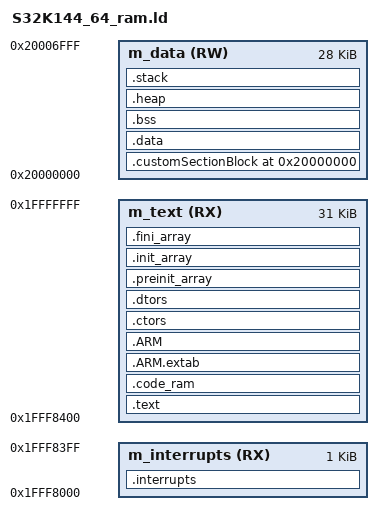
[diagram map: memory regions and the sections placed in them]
/*
** ###################################################################
**     Processor:           S32K144 with 64 KB SRAM
**     Compiler:            GNU C Compiler
**
**     Abstract:
**         Linker file for the GNU C Compiler
**
**     Copyright (c) 2015-2016 Freescale Semiconductor, Inc.
**     Copyright 2017 NXP
**     All rights reserved.
**
**     THIS SOFTWARE IS PROVIDED BY NXP "AS IS" AND ANY EXPRESSED OR
**     IMPLIED WARRANTIES, INCLUDING, BUT NOT LIMITED TO, THE IMPLIED WARRANTIES
**     OF MERCHANTABILITY AND FITNESS FOR A PARTICULAR PURPOSE ARE DISCLAIMED.
**     IN NO EVENT SHALL NXP OR ITS CONTRIBUTORS BE LIABLE FOR ANY DIRECT,
**     INDIRECT, INCIDENTAL, SPECIAL, EXEMPLARY, OR CONSEQUENTIAL DAMAGES
**     (INCLUDING, BUT NOT LIMITED TO, PROCUREMENT OF SUBSTITUTE GOODS OR
**     SERVICES; LOSS OF USE, DATA, OR PROFITS; OR BUSINESS INTERRUPTION)
**     HOWEVER CAUSED AND ON ANY THEORY OF LIABILITY, WHETHER IN CONTRACT,
**     STRICT LIABILITY, OR TORT (INCLUDING NEGLIGENCE OR OTHERWISE) ARISING
**     IN ANY WAY OUT OF THE USE OF THIS SOFTWARE, EVEN IF ADVISED OF
**     THE POSSIBILITY OF SUCH DAMAGE.
**
**     http:                 www.freescale.com
**     mail:                 support@freescale.com
**
** ###################################################################
*/

/* Entry Point */
ENTRY(Reset_Handler)

/*
To use "new" operator with EWL in C++ project the following symbol shall be defined
*/
/*EXTERN(_ZN10__cxxabiv119__terminate_handlerE)*/

HEAP_SIZE  = DEFINED(__heap_size__)  ? __heap_size__  : 0x00000400;
STACK_SIZE = DEFINED(__stack_size__) ? __stack_size__ : 0x00000400;

/* Specify the memory areas */
MEMORY
{
  /* SRAM_L */
  m_interrupts          (RX)  : ORIGIN = 0x1FFF8000, LENGTH = 0x00000400
  m_text                (RX)  : ORIGIN = 0x1FFF8400, LENGTH = 0x00007C00

  /* SRAM_U */
  m_data                (RW)  : ORIGIN = 0x20000000, LENGTH = 0x00007000
}

/* Define output sections */
SECTIONS
{
  /* The startup code goes first into internal RAM */
  .interrupts :
  {
    __VECTOR_TABLE = .;
    __interrupts_start__ = .;
    . = ALIGN(4);
    KEEP(*(.isr_vector))     /* Startup code */
    __interrupts_end__ = .;
    . = ALIGN(4);
  } > m_interrupts

  __VECTOR_RAM = __VECTOR_TABLE;
  __RAM_VECTOR_TABLE_SIZE = 0x0;

  /* The program code and other data goes into internal RAM */
  .text :
  {
    . = ALIGN(4);
    *(.text)                 /* .text sections (code) */
    *(.text*)                /* .text* sections (code) */
    *(.rodata)               /* .rodata sections (constants, strings, etc.) */
    *(.rodata*)              /* .rodata* sections (constants, strings, etc.) */
    *(.glue_7)               /* glue arm to thumb code */
    *(.glue_7t)              /* glue thumb to arm code */
    *(.eh_frame)
    KEEP (*(.init))
    KEEP (*(.fini))
    . = ALIGN(4);
  } > m_text

  /* Section for storing functions that needs to execute from RAM */
  .code_ram :
  {
    . = ALIGN(4);
    __CODE_RAM = .;
    __code_ram_start__ = .;
    *(.code_ram)               /* Custom section for storing code in RAM */
    __CODE_ROM = .;            /* Symbol is used by start-up for data initialization. */
    __CODE_END = .;            /* No copy */
    __code_ram_end__ = .;
    . = ALIGN(4);
  } > m_text

  .ARM.extab :
  {
    *(.ARM.extab* .gnu.linkonce.armextab.*)
  } > m_text

  .ARM :
  {
    __exidx_start = .;
    *(.ARM.exidx*)
    __exidx_end = .;
  } > m_text

 .ctors :
  {
    __CTOR_LIST__ = .;
    /* gcc uses crtbegin.o to find the start of
       the constructors, so we make sure it is
       first.  Because this is a wildcard, it
       doesn't matter if the user does not
       actually link against crtbegin.o; the
       linker won't look for a file to match a
       wildcard.  The wildcard also means that it
       doesn't matter which directory crtbegin.o
       is in.  */
    KEEP (*crtbegin.o(.ctors))
    KEEP (*crtbegin?.o(.ctors))
    /* We don't want to include the .ctor section from
       from the crtend.o file until after the sorted ctors.
       The .ctor section from the crtend file contains the
       end of ctors marker and it must be last */
    KEEP (*(EXCLUDE_FILE(*crtend?.o *crtend.o) .ctors))
    KEEP (*(SORT(.ctors.*)))
    KEEP (*(.ctors))
    __CTOR_END__ = .;
  } > m_text

  .dtors :
  {
    __DTOR_LIST__ = .;
    KEEP (*crtbegin.o(.dtors))
    KEEP (*crtbegin?.o(.dtors))
    KEEP (*(EXCLUDE_FILE(*crtend?.o *crtend.o) .dtors))
    KEEP (*(SORT(.dtors.*)))
    KEEP (*(.dtors))
    __DTOR_END__ = .;
  } > m_text

  .preinit_array :
  {
    PROVIDE_HIDDEN (__preinit_array_start = .);
    KEEP (*(.preinit_array*))
    PROVIDE_HIDDEN (__preinit_array_end = .);
  } > m_text

  .init_array :
  {
    PROVIDE_HIDDEN (__init_array_start = .);
    KEEP (*(SORT(.init_array.*)))
    KEEP (*(.init_array*))
    PROVIDE_HIDDEN (__init_array_end = .);
  } > m_text

  .fini_array :
  {
    PROVIDE_HIDDEN (__fini_array_start = .);
    KEEP (*(SORT(.fini_array.*)))
    KEEP (*(.fini_array*))
    PROVIDE_HIDDEN (__fini_array_end = .);
  } > m_text

  __etext = .;    /* Define a global symbol at end of code. */
  __DATA_ROM = .; /* Symbol is used by startup for data initialization. */
  __DATA_END = __DATA_ROM; /* No copy */

  /* Custom Section Block that can be used to place data at absolute address. */
  /* Use __attribute__((section (".customSection"))) to place data here. */
  .customSectionBlock  ORIGIN(m_data) :
  {
    __customSection_start__ = .;
    KEEP(*(.customSection))  /* Keep section even if not referenced. */
    __customSection_end__ = .;
    __CUSTOM_ROM = .;
    __CUSTOM_END = .;
  } > m_data

  .data :
  {
    . = ALIGN(4);
    __DATA_RAM = .;
    __data_start__ = .;      /* Create a global symbol at data start. */
    *(.data)                 /* .data sections */
    *(.data*)                /* .data* sections */
    KEEP(*(.jcr*))
    . = ALIGN(4);
    __data_end__ = .;        /* Define a global symbol at data end. */
  } > m_data

  /* Uninitialized data section. */
  .bss :
  {
    /* This is used by the startup in order to initialize the .bss section. */
    . = ALIGN(4);
    __BSS_START = .;
    __bss_start__ = .;
    *(.bss)
    *(.bss*)
    *(COMMON)
    . = ALIGN(4);
    __bss_end__ = .;
    __BSS_END = .;
  } > m_data

  .heap :
  {
    . = ALIGN(8);
    __end__ = .;
    __heap_start__ = .;
    PROVIDE(end = .);
    PROVIDE(_end = .);
    PROVIDE(__end = .);
    __HeapBase = .;
    . += HEAP_SIZE;
    __HeapLimit = .;
    __heap_limit = .;
    __heap_end__ = .;
  } > m_data

  /* Initializes stack on the end of block */
  __StackTop   = ORIGIN(m_data) + LENGTH(m_data);
  __StackLimit = __StackTop - STACK_SIZE;
  PROVIDE(__stack = __StackTop);
  
  .stack __StackLimit :
  {
    . = ALIGN(8);
    __stack_start__ = .;
    . += STACK_SIZE;
    __stack_end__ = .;
  } > m_data

  /* Labels required by EWL */
  __START_BSS = __BSS_START;
  __END_BSS = __BSS_END;
  __SP_INIT = __StackTop;  
  
  .ARM.attributes 0 : { *(.ARM.attributes) }

  ASSERT(__StackLimit >= __HeapLimit, "region m_data overflowed with stack and heap")

  /DISCARD/ : {
  *(.FlashConfig)
  }
}

